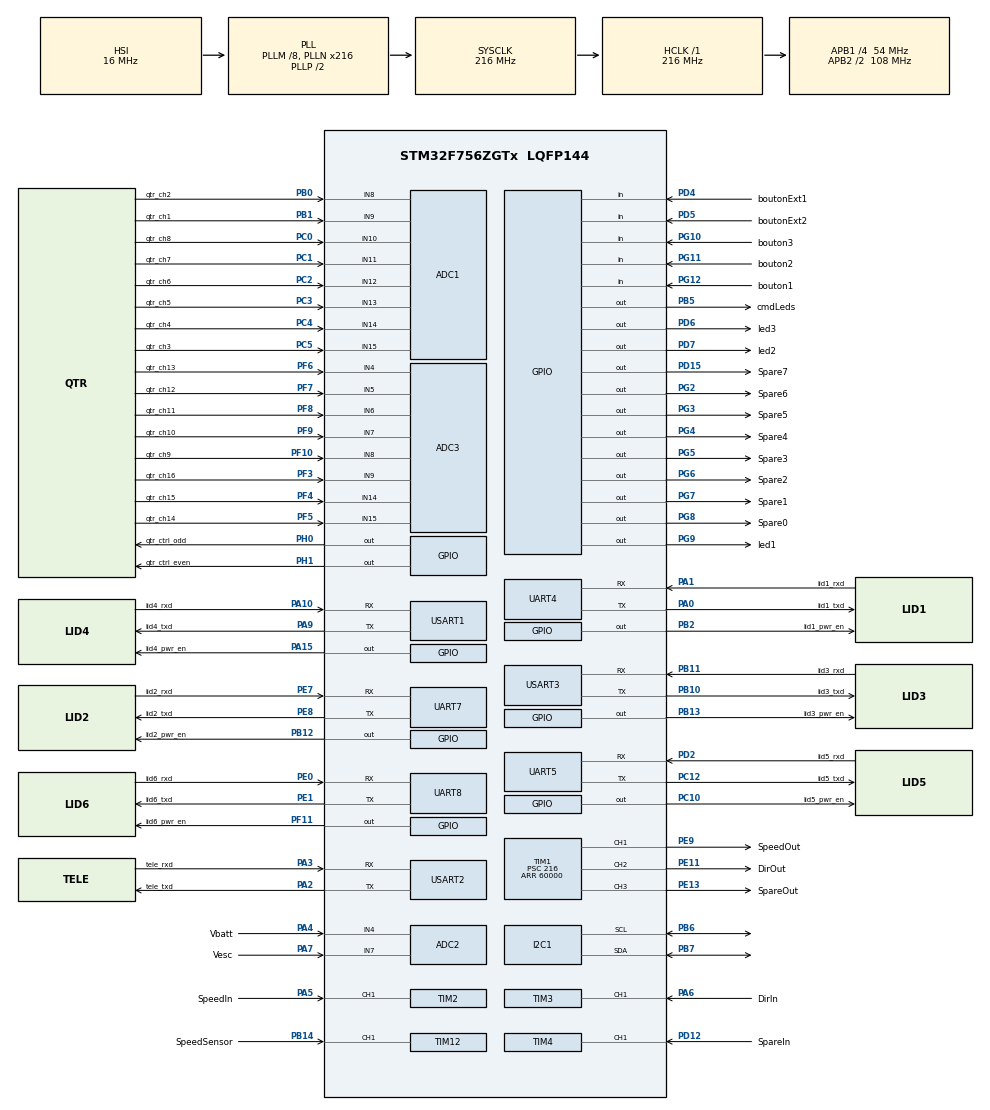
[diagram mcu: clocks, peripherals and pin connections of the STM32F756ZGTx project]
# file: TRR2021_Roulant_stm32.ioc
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ADC1.Channel-2\#ChannelRegularConversion=ADC_CHANNEL_15
ADC1.NbrOfConversionFlag=1
ADC1.Rank-2\#ChannelRegularConversion=1
ADC1.SamplingTime-2\#ChannelRegularConversion=ADC_SAMPLETIME_3CYCLES
ADC1.master=1
ADC2.Channel-0\#ChannelRegularConversion=ADC_CHANNEL_7
ADC2.NbrOfConversionFlag=1
ADC2.Rank-0\#ChannelRegularConversion=1
ADC2.SamplingTime-0\#ChannelRegularConversion=ADC_SAMPLETIME_3CYCLES
ADC3.Channel-0\#ChannelRegularConversion=ADC_CHANNEL_15
ADC3.NbrOfConversionFlag=1
ADC3.Rank-0\#ChannelRegularConversion=1
ADC3.SamplingTime-0\#ChannelRegularConversion=ADC_SAMPLETIME_3CYCLES
Dma.Request0=UART4_RX
Dma.Request1=UART8_RX
Dma.Request2=UART5_RX
Dma.Request3=UART7_RX
Dma.UART4_RX.0.Direction=DMA_PERIPH_TO_MEMORY
Dma.UART4_RX.0.FIFOMode=DMA_FIFOMODE_DISABLE
Dma.UART4_RX.0.Instance=DMA1_Stream2
Dma.UART4_RX.0.MemDataAlignment=DMA_MDATAALIGN_BYTE
Dma.UART4_RX.0.MemInc=DMA_MINC_ENABLE
Dma.UART4_RX.0.Mode=DMA_NORMAL
Dma.UART4_RX.0.PeriphDataAlignment=DMA_PDATAALIGN_BYTE
Dma.UART4_RX.0.PeriphInc=DMA_PINC_DISABLE
Dma.UART4_RX.0.Priority=DMA_PRIORITY_LOW
Dma.UART5_RX.2.Direction=DMA_PERIPH_TO_MEMORY
Dma.UART5_RX.2.FIFOMode=DMA_FIFOMODE_DISABLE
Dma.UART5_RX.2.Instance=DMA1_Stream0
Dma.UART5_RX.2.MemDataAlignment=DMA_MDATAALIGN_BYTE
Dma.UART5_RX.2.MemInc=DMA_MINC_ENABLE
Dma.UART5_RX.2.Mode=DMA_NORMAL
Dma.UART5_RX.2.PeriphDataAlignment=DMA_PDATAALIGN_BYTE
Dma.UART5_RX.2.PeriphInc=DMA_PINC_DISABLE
Dma.UART5_RX.2.Priority=DMA_PRIORITY_LOW
Dma.UART7_RX.3.Direction=DMA_PERIPH_TO_MEMORY
Dma.UART7_RX.3.FIFOMode=DMA_FIFOMODE_DISABLE
Dma.UART7_RX.3.Instance=DMA1_Stream3
Dma.UART7_RX.3.MemDataAlignment=DMA_MDATAALIGN_BYTE
Dma.UART7_RX.3.MemInc=DMA_MINC_ENABLE
Dma.UART7_RX.3.Mode=DMA_NORMAL
Dma.UART7_RX.3.PeriphDataAlignment=DMA_PDATAALIGN_BYTE
Dma.UART7_RX.3.PeriphInc=DMA_PINC_DISABLE
Dma.UART7_RX.3.Priority=DMA_PRIORITY_LOW
Dma.UART8_RX.1.Direction=DMA_PERIPH_TO_MEMORY
Dma.UART8_RX.1.FIFOMode=DMA_FIFOMODE_DISABLE
Dma.UART8_RX.1.Instance=DMA1_Stream6
Dma.UART8_RX.1.MemDataAlignment=DMA_MDATAALIGN_BYTE
Dma.UART8_RX.1.MemInc=DMA_MINC_ENABLE
Dma.UART8_RX.1.Mode=DMA_NORMAL
Dma.UART8_RX.1.PeriphDataAlignment=DMA_PDATAALIGN_BYTE
Dma.UART8_RX.1.PeriphInc=DMA_PINC_DISABLE
Dma.UART8_RX.1.Priority=DMA_PRIORITY_LOW
I2C1.Timing=0x20404768
Mcu.Family=STM32F7
Mcu.Name=STM32F756ZGTx
Mcu.Package=LQFP144
NVIC.DMA1_Stream0_IRQn=true\:0\:0\:false\:false\:true\:false\:true
NVIC.DMA1_Stream2_IRQn=true\:0\:0\:false\:false\:true\:false\:true
NVIC.DMA1_Stream3_IRQn=true\:0\:0\:false\:false\:true\:false\:true
NVIC.DMA1_Stream6_IRQn=true\:0\:0\:false\:false\:true\:false\:true
NVIC.PriorityGroup=NVIC_PRIORITYGROUP_4
NVIC.TIM2_IRQn=true\:0\:0\:false\:false\:true\:true\:true
NVIC.TIM3_IRQn=true\:0\:0\:false\:false\:true\:true\:true
NVIC.TIM4_IRQn=true\:0\:0\:false\:false\:true\:true\:true
NVIC.TIM8_BRK_TIM12_IRQn=true\:0\:0\:false\:false\:true\:true\:true
NVIC.UART4_IRQn=true\:0\:0\:false\:false\:true\:true\:true
NVIC.UART5_IRQn=true\:0\:0\:false\:false\:true\:true\:true
NVIC.UART7_IRQn=true\:0\:0\:false\:false\:true\:true\:true
NVIC.UART8_IRQn=true\:0\:0\:false\:false\:true\:true\:true
PA0/WKUP.GPIO_Label=lid1_txd
PA0/WKUP.GPIO_PuPd=GPIO_PULLUP
PA0/WKUP.Mode=Asynchronous
PA0/WKUP.Signal=UART4_TX
PA1.GPIO_Label=lid1_rxd
PA1.GPIO_PuPd=GPIO_PULLUP
PA1.Mode=Asynchronous
PA1.Signal=UART4_RX
PA10.GPIO_Label=lid4_rxd
PA10.Mode=Asynchronous
PA10.Signal=USART1_RX
PA13.Signal=SYS_JTMS-SWDIO
PA14.Signal=SYS_JTCK-SWCLK
PA15.GPIO_Label=lid4_pwr_en
PA15.Signal=GPIO_Output
PA2.GPIO_Label=tele_txd
PA2.GPIO_Speed=GPIO_SPEED_FREQ_LOW
PA2.Mode=Asynchronous
PA2.Signal=USART2_TX
PA3.GPIO_Label=tele_rxd
PA3.GPIO_Speed=GPIO_SPEED_FREQ_LOW
PA3.Mode=Asynchronous
PA3.Signal=USART2_RX
PA4.GPIO_Label=Vbatt
PA4.Signal=ADCx_IN4
PA5.GPIO_Label=SpeedIn
PA5.Signal=S_TIM2_CH1_ETR
PA6.GPIO_Label=DirIn
PA6.Signal=S_TIM3_CH1
PA7.GPIO_Label=Vesc
PA7.Signal=ADCx_IN7
PA9.GPIO_Label=lid4_txd
PA9.Mode=Asynchronous
PA9.Signal=USART1_TX
PB0.GPIO_Label=qtr_ch2
PB0.Signal=ADCx_IN8
PB1.GPIO_Label=qtr_ch1
PB1.Signal=ADCx_IN9
PB10.GPIO_Label=lid3_txd
PB10.Mode=Asynchronous
PB10.Signal=USART3_TX
PB11.GPIO_Label=lid3_rxd
PB11.Mode=Asynchronous
PB11.Signal=USART3_RX
PB12.GPIO_Label=lid2_pwr_en
PB12.Signal=GPIO_Output
PB13.GPIO_Label=lid3_pwr_en
PB13.Signal=GPIO_Output
PB14.GPIO_Label=SpeedSensor
PB14.Signal=S_TIM12_CH1
PB2.GPIO_Label=lid1_pwr_en
PB2.Signal=GPIO_Output
PB5.GPIO_Label=cmdLeds
PB5.Signal=GPIO_Output
PB6.Mode=I2C
PB6.Signal=I2C1_SCL
PB7.Mode=I2C
PB7.Signal=I2C1_SDA
PC0.GPIO_Label=qtr_ch8
PC0.Signal=ADCx_IN10
PC1.GPIO_Label=qtr_ch7
PC1.Signal=ADCx_IN11
PC10.GPIO_Label=lid5_pwr_en
PC10.Signal=GPIO_Output
PC12.GPIO_Label=lid5_txd
PC12.GPIO_PuPd=GPIO_PULLUP
PC12.Mode=Asynchronous
PC12.Signal=UART5_TX
PC2.GPIO_Label=qtr_ch6
PC2.Signal=ADCx_IN12
PC3.GPIO_Label=qtr_ch5
PC3.Signal=ADCx_IN13
PC4.GPIO_Label=qtr_ch4
PC4.Signal=ADCx_IN14
PC5.GPIO_Label=qtr_ch3
PC5.Signal=ADCx_IN15
PD12.GPIO_Label=SpareIn
PD12.GPIO_PuPd=GPIO_PULLUP
PD12.Signal=S_TIM4_CH1
PD15.GPIO_Label=Spare7
PD15.Signal=GPIO_Output
PD2.GPIO_Label=lid5_rxd
PD2.GPIO_PuPd=GPIO_PULLUP
PD2.Mode=Asynchronous
PD2.Signal=UART5_RX
PD4.GPIO_Label=boutonExt1
PD4.Signal=GPIO_Input
PD5.GPIO_Label=boutonExt2
PD5.Signal=GPIO_Input
PD6.GPIO_Label=led3
PD6.Signal=GPIO_Output
PD7.GPIO_Label=led2
PD7.Signal=GPIO_Output
PE0.GPIO_Label=lid6_rxd
PE0.GPIO_PuPd=GPIO_PULLUP
PE0.Mode=Asynchronous
PE0.Signal=UART8_RX
PE1.GPIO_Label=lid6_txd
PE1.GPIO_PuPd=GPIO_PULLUP
PE1.Mode=Asynchronous
PE1.Signal=UART8_TX
PE11.GPIO_Label=DirOut
PE11.Signal=S_TIM1_CH2
PE13.GPIO_Label=SpareOut
PE13.Signal=S_TIM1_CH3
PE7.GPIO_Label=lid2_rxd
PE7.GPIO_PuPd=GPIO_PULLUP
PE7.Mode=Asynchronous
PE7.Signal=UART7_RX
PE8.GPIO_Label=lid2_txd
PE8.GPIO_PuPd=GPIO_PULLUP
PE8.Mode=Asynchronous
PE8.Signal=UART7_TX
PE9.GPIO_Label=SpeedOut
PE9.Signal=S_TIM1_CH1
PF10.GPIO_Label=qtr_ch9
PF10.Mode=IN8
PF10.Signal=ADC3_IN8
PF11.GPIO_Label=lid6_pwr_en
PF11.Signal=GPIO_Output
PF3.GPIO_Label=qtr_ch16
PF3.Mode=IN9
PF3.Signal=ADC3_IN9
PF4.GPIO_Label=qtr_ch15
PF4.Mode=IN14
PF4.Signal=ADC3_IN14
PF5.GPIO_Label=qtr_ch14
PF5.Mode=IN15
PF5.Signal=ADC3_IN15
PF6.GPIO_Label=qtr_ch13
PF6.Mode=IN4
PF6.Signal=ADC3_IN4
PF7.GPIO_Label=qtr_ch12
PF7.Mode=IN5
PF7.Signal=ADC3_IN5
PF8.GPIO_Label=qtr_ch11
PF8.Mode=IN6
PF8.Signal=ADC3_IN6
PF9.GPIO_Label=qtr_ch10
PF9.Mode=IN7
PF9.Signal=ADC3_IN7
PG10.GPIO_Label=bouton3
PG10.Signal=GPIO_Input
PG11.GPIO_Label=bouton2
PG11.Signal=GPIO_Input
PG12.GPIO_Label=bouton1
PG12.Signal=GPIO_Input
PG2.GPIO_Label=Spare6
PG2.Signal=GPIO_Output
PG3.GPIO_Label=Spare5
PG3.Signal=GPIO_Output
PG4.GPIO_Label=Spare4
PG4.Signal=GPIO_Output
PG5.GPIO_Label=Spare3
PG5.Signal=GPIO_Output
PG6.GPIO_Label=Spare2
PG6.Signal=GPIO_Output
PG7.GPIO_Label=Spare1
PG7.Signal=GPIO_Output
PG8.GPIO_Label=Spare0
PG8.Signal=GPIO_Output
PG9.GPIO_Label=led1
PG9.Signal=GPIO_Output
PH0/OSC_IN.GPIO_Label=qtr_ctrl_odd
PH0/OSC_IN.Signal=GPIO_Output
PH1/OSC_OUT.GPIO_Label=qtr_ctrl_even
PH1/OSC_OUT.Signal=GPIO_Output
ProjectManager.HeapSize=0x200
ProjectManager.StackSize=0x400
ProjectManager.TargetToolchain=STM32CubeIDE
RCC.AHBFreq_Value=216000000
RCC.APB1CLKDivider=RCC_HCLK_DIV4
RCC.APB1Freq_Value=54000000
RCC.APB1TimFreq_Value=108000000
RCC.APB2CLKDivider=RCC_HCLK_DIV2
RCC.APB2Freq_Value=108000000
RCC.APB2TimFreq_Value=216000000
RCC.CortexFreq_Value=216000000
RCC.HCLKFreq_Value=216000000
RCC.HSE_VALUE=25000000
RCC.HSI_VALUE=16000000
RCC.LSE_VALUE=32768
RCC.PLLM=8
RCC.PLLN=216
RCC.SYSCLKFreq_VALUE=216000000
RCC.SYSCLKSource=RCC_SYSCLKSOURCE_PLLCLK
RCC.USBFreq_Value=216000000
RCC.VCOOutputFreq_Value=432000000
SH.ADCx_IN10.0=ADC1_IN10,IN10
SH.ADCx_IN11.0=ADC1_IN11,IN11
SH.ADCx_IN12.0=ADC1_IN12,IN12
SH.ADCx_IN13.0=ADC1_IN13,IN13
SH.ADCx_IN14.0=ADC1_IN14,IN14
SH.ADCx_IN15.0=ADC1_IN15,IN15
SH.ADCx_IN4.0=ADC2_IN4,IN4
SH.ADCx_IN7.0=ADC2_IN7,IN7
SH.ADCx_IN8.0=ADC1_IN8,IN8
SH.ADCx_IN9.0=ADC1_IN9,IN9
SH.S_TIM12_CH1.0=TIM12_CH1,PWM_Input_1
SH.S_TIM1_CH1.0=TIM1_CH1,PWM Generation1 CH1
SH.S_TIM1_CH2.0=TIM1_CH2,PWM Generation2 CH2
SH.S_TIM1_CH3.0=TIM1_CH3,PWM Generation3 CH3
SH.S_TIM2_CH1_ETR.0=TIM2_CH1,PWM_Input_1
SH.S_TIM3_CH1.0=TIM3_CH1,PWM_Input_1
SH.S_TIM4_CH1.0=TIM4_CH1,PWM_Input_1
TIM1.Channel-PWM\ Generation1\ CH1=TIM_CHANNEL_1
TIM1.Channel-PWM\ Generation2\ CH2=TIM_CHANNEL_2
TIM1.Channel-PWM\ Generation3\ CH3=TIM_CHANNEL_3
TIM1.Period=60000
TIM1.Prescaler=216
TIM1.Pulse-PWM\ Generation1\ CH1=1500
TIM1.Pulse-PWM\ Generation2\ CH2=1000
TIM12.Period=65535
TIM12.Prescaler=108
TIM2.Period=65535
TIM2.Prescaler=108
TIM3.Period=65535
TIM3.Prescaler=108
TIM4.Period=65535
TIM4.Prescaler=108
UART5.DMADisableonRxErrorParam=UART_ADVFEATURE_DMA_ENABLEONRXERROR
UART5.OverrunDisableParam=UART_ADVFEATURE_OVERRUN_DISABLE
USART1.VirtualMode-Asynchronous=VM_ASYNC
USART2.VirtualMode-Asynchronous=VM_ASYNC
USART3.VirtualMode-Asynchronous=VM_ASYNC
VP_TIM12_VS_ClockSourceINT.Mode=Internal
VP_TIM1_VS_ClockSourceINT.Mode=Internal
VP_TIM2_VS_ClockSourceINT.Mode=Internal
VP_TIM3_VS_ClockSourceINT.Mode=Internal
VP_TIM4_VS_ClockSourceINT.Mode=Internal
VP_TIM8_VS_ClockSourceINT.Mode=Internal
board=custom

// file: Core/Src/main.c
/* USER CODE BEGIN Header */
/**
  ******************************************************************************
  * @file           : main.c
  * @brief          : Main program body
  ******************************************************************************
  * @attention
  *
  * <h2><center>&copy; Copyright (c) 2021 STMicroelectronics.
  * All rights reserved.</center></h2>
  *
  * This software component is licensed by ST under BSD 3-Clause license,
  * the "License"; You may not use this file except in compliance with the
  * License. You may obtain a copy of the License at:
  *                        opensource.org/licenses/BSD-3-Clause
  *
  ******************************************************************************
  */
/* USER CODE END Header */
#include "main.h"

/* USER CODE BEGIN Includes */
#include "stdio.h"
#include "tfminiplus.h"
#include "radio_commandes.h"
#include "imu.h"
#include "pid.h"
#include "algo_suivi_bords.h"
#include "parametres_configuration.h"
#include "telemetrie.h"
/* USER CODE END Includes */

/* USER CODE BEGIN PTD */
typedef enum { automate_principal_radio, automate_principal_autonome, automate_principal_shell } eEtatsAutomatePrincipal;
/* USER CODE END PTD */

ADC_HandleTypeDef hadc1;
ADC_HandleTypeDef hadc2;
ADC_HandleTypeDef hadc3;

I2C_HandleTypeDef hi2c1;

TIM_HandleTypeDef htim1;
TIM_HandleTypeDef htim2;
TIM_HandleTypeDef htim3;
TIM_HandleTypeDef htim4;
TIM_HandleTypeDef htim8;
TIM_HandleTypeDef htim12;

UART_HandleTypeDef huart4;
UART_HandleTypeDef huart5;
UART_HandleTypeDef huart7;
UART_HandleTypeDef huart8;
UART_HandleTypeDef huart1;
UART_HandleTypeDef huart2;
UART_HandleTypeDef huart3;
DMA_HandleTypeDef hdma_uart4_rx;
DMA_HandleTypeDef hdma_uart5_rx;
DMA_HandleTypeDef hdma_uart7_rx;
DMA_HandleTypeDef hdma_uart8_rx;

/* USER CODE BEGIN PV */
extern int gUpdateGyro;
extern eEtatsAutomateAutomatique etat_automate_automatique;
//extern st_telemetrie gTelemetrie;

eEtatsAutomatePrincipal etat_automate_principal;
/* USER CODE END PV */

void SystemClock_Config(void);
static void MX_GPIO_Init(void);
static void MX_I2C1_Init(void);
static void MX_TIM1_Init(void);
static void MX_TIM2_Init(void);
static void MX_TIM3_Init(void);
static void MX_TIM4_Init(void);
static void MX_TIM8_Init(void);
static void MX_UART4_Init(void);
static void MX_UART5_Init(void);
static void MX_UART7_Init(void);
static void MX_UART8_Init(void);
static void MX_USART1_UART_Init(void);
static void MX_USART2_UART_Init(void);
static void MX_USART3_UART_Init(void);
static void MX_ADC1_Init(void);
static void MX_ADC3_Init(void);
static void MX_ADC2_Init(void);
static void MX_DMA_Init(void);
static void MX_TIM12_Init(void);
/* USER CODE BEGIN PFP */
extern void shell();
/* USER CODE END PFP */

/* USER CODE BEGIN 0 */
int __io_putchar(int ch)
{

	uint8_t ch8=ch;

	HAL_UART_Transmit(&huart2,(uint8_t *)&ch8,1,HAL_MAX_DELAY);

	return ch;

}

int __io_getchar()
{

	int ch8;
	HAL_StatusTypeDef retour;

	ch8 = ' ';

	do {
		retour = HAL_UART_Receive(&huart2,(uint8_t*)&ch8,1,HAL_MAX_DELAY);
		//delay_ms(1);
	} while(retour != HAL_OK);

		if(retour != HAL_OK)
			ch8 = -1;

return ch8;

}

/* USER CODE END 0 */

int main(void)
{
  /* USER CODE BEGIN 1 */
	uint32_t current_time;
	uint8_t filtre_declenchement_auto;
	uint32_t last_time_gyro;
	uint16_t temps_appui_boutonext1, temps_relachement_boutonext1;
	uint16_t temps_appui_boutonext2;
	float direction, throttle, distance, distance_precedente, vitesse;
	st_tele_element *pTeleElement;
	st_context_robot robot_contexte;
	int erreur;
  /* USER CODE END 1 */

  /* MCU Configuration--------------------------------------------------------*/

  /* Reset of all peripherals, Initializes the Flash interface and the Systick. */
  HAL_Init();

  /* Configure the system clock */
  SystemClock_Config();

  /* Initialize all configured peripherals */
  MX_GPIO_Init();
  MX_DMA_Init();
  MX_I2C1_Init();
  MX_TIM1_Init();
  MX_TIM2_Init();
  MX_TIM3_Init();
  MX_TIM4_Init();
  MX_TIM8_Init();
  MX_UART4_Init();
  MX_UART5_Init();
  MX_UART7_Init();
  MX_UART8_Init();
  MX_USART1_UART_Init();
  MX_USART2_UART_Init();
  MX_USART3_UART_Init();
  MX_ADC1_Init();
  MX_ADC3_Init();
  MX_ADC2_Init();

  MX_TIM12_Init();
  /* USER CODE BEGIN 2 */

  printf("+++++++ Buggy TRR 2022 Roulant +++++++\r\n");

  // Initialisation des Lidars
  tfminiplus_init();

  // Initialisation de la gestion radio et commande vehicule
  init_radio_commandes();

  // Récupération des parametres de conf
  paramConf_restaure();

  // Gyro
  if(gyro_init() == GYRO_OK)
  {
	  last_time_gyro = HAL_GetTick();
	  while(gyro_is_calibrated())
	  {
		  HAL_Delay(1);
		  current_time = HAL_GetTick();
		  gyro_auto_calibrate(current_time - last_time_gyro);
		  last_time_gyro = current_time;
	  }
	  printf("Gyro calibrated\r\n");
	  gUpdateGyro = 1;
	  gyro_reset_heading();
  }
  else
	  printf("Erreur d'initialisation du Gyro\r\n");

  // Télémetrie
  telemetrie_init();
  pTeleElement = telemetrie_pt_enreg_en_cours();
  erreur = 0;

  // Initialisation des variables
  temps_appui_boutonext1 = 0;
  temps_relachement_boutonext1 = 0;
  temps_appui_boutonext2 = 0;
  distance = 0;
  distance_precedente = 0;

  /* USER CODE END 2 */

  /* Infinite loop */
  while (1)
  {

    /* USER CODE BEGIN 3 */
	  if(HAL_GPIO_ReadPin(boutonExt1_GPIO_Port, boutonExt1_Pin)==GPIO_PIN_RESET)
	  {
		  temps_appui_boutonext1 += 10; // La durée d'appui du bouton est allongée de 10 ms
		  temps_relachement_boutonext1 = 0;
	  }
	  else
	  {
		  temps_appui_boutonext1 = 0;
		  if(temps_relachement_boutonext1 < 60000) // on limite sinon le compteur partirait en dépassement
			  temps_relachement_boutonext1 += 10;
	  }
	  if(HAL_GPIO_ReadPin(boutonExt2_GPIO_Port, boutonExt2_Pin)==GPIO_PIN_RESET)
		  temps_appui_boutonext2 += 10; // La durée d'appui du bouton est allongée de 10 ms
	  else
		  temps_appui_boutonext2 = 0;

	  gyro_update(0.01);

	  switch(etat_automate_principal)
	  {
	  case automate_principal_radio :
		  // Bandeau de lumière couleur xxx
		  // Par défaut aujourd'hui allume led verte
		  HAL_GPIO_WritePin(led1_GPIO_Port, led1_Pin, GPIO_PIN_SET);
		  HAL_GPIO_WritePin(led2_GPIO_Port, led2_Pin, GPIO_PIN_RESET);
		  HAL_GPIO_WritePin(led3_GPIO_Port, led3_Pin, GPIO_PIN_SET);

		  if(temps_appui_boutonext1 > 1000)
		  {
			  algo_init(&robot_contexte);
			  filtre_declenchement_auto = 0;
			  etat_automate_principal = automate_principal_autonome;
		  }
		  else if(temps_appui_boutonext2 > 1000)
		  {
			  etat_automate_principal = automate_principal_shell;
		  }
		  else
		  {
			  // On reste dans l'état actuel.
			  // On recopie les commandes de la radio vers le véhicule
				radio_dir_get(&direction);
				radio_throttle_get(&throttle);
				vehicule_dir_set(direction);
				vehicule_throttle_set(throttle);

//				vehicule_distance_aimant_get(&distance);
//				vitesse = (distance-distance_precedente)/0.01;
//				distance_precedente = distance;
//
//				printf("%f;%f;%f\r\n", throttle, vitesse, distance);
		  }
		  break;
	  case automate_principal_autonome :
		  // Bandeau de lumière couleur xxx
		  // Par défaut aujourd'hui allume led rouge
		  HAL_GPIO_WritePin(led1_GPIO_Port, led1_Pin, GPIO_PIN_RESET);
		  HAL_GPIO_WritePin(led2_GPIO_Port, led2_Pin, GPIO_PIN_SET);
		  HAL_GPIO_WritePin(led3_GPIO_Port, led3_Pin, GPIO_PIN_SET);

		  // On attend le relachement du bouton puis 2 secondes,
		  // le temps que la personne retire complètement son doigt de l'environnement du robot
		  if((temps_relachement_boutonext1>2000) && (filtre_declenchement_auto == 0))
			  filtre_declenchement_auto = 1;

		  if(filtre_declenchement_auto == 1)
			  // Appel automate
			  algo_decouverte(&robot_contexte, 0.01);

		  // Si le pilote tente de reprendre le controle passage immédiat des commandes
		  // Si le tour de piste en automatique est fini alors passage des commandes à la radio
		  if((radio_isThereCommand() != 0) || (etat_automate_automatique == automate_auto_fini))
		  {
			  printf("T;Fin;\r\n");
			  etat_automate_principal = automate_principal_radio;

		  }
//		  else
//		  {
//			  // Appel de l'automate automatique
//		  }
		  break;
	  case automate_principal_shell :
		  // Bandeau de lumière couleur xxx
		  // Par défaut aujourd'hui allume led bleue
		  HAL_GPIO_WritePin(led1_GPIO_Port, led1_Pin, GPIO_PIN_SET);
		  HAL_GPIO_WritePin(led2_GPIO_Port, led2_Pin, GPIO_PIN_SET);
		  HAL_GPIO_WritePin(led3_GPIO_Port, led3_Pin, GPIO_PIN_RESET);

		  // Lancement du shell
		  shell();

		  telemetrie_init();
		  pTeleElement = telemetrie_pt_enreg_en_cours();
		  erreur = 0;

		  etat_automate_principal = automate_principal_radio;
		  break;
	  default :
		  etat_automate_principal = automate_principal_radio;
		  break;

	  }

	  // Iteration de l'automate principale toutes les 10 ms.
	  HAL_Delay(10);
  }
  /* USER CODE END 3 */
}

void SystemClock_Config(void)
{
  RCC_OscInitTypeDef RCC_OscInitStruct = {0};
  RCC_ClkInitTypeDef RCC_ClkInitStruct = {0};
  RCC_PeriphCLKInitTypeDef PeriphClkInitStruct = {0};

  /** Configure the main internal regulator output voltage
  */
  __HAL_RCC_PWR_CLK_ENABLE();
  __HAL_PWR_VOLTAGESCALING_CONFIG(PWR_REGULATOR_VOLTAGE_SCALE1);
  /** Initializes the RCC Oscillators according to the specified parameters
  * in the RCC_OscInitTypeDef structure.
  */
  RCC_OscInitStruct.OscillatorType = RCC_OSCILLATORTYPE_HSI;
  RCC_OscInitStruct.HSIState = RCC_HSI_ON;
  RCC_OscInitStruct.HSICalibrationValue = RCC_HSICALIBRATION_DEFAULT;
  RCC_OscInitStruct.PLL.PLLState = RCC_PLL_ON;
  RCC_OscInitStruct.PLL.PLLSource = RCC_PLLSOURCE_HSI;
  RCC_OscInitStruct.PLL.PLLM = 8;
  RCC_OscInitStruct.PLL.PLLN = 216;
  RCC_OscInitStruct.PLL.PLLP = RCC_PLLP_DIV2;
  RCC_OscInitStruct.PLL.PLLQ = 2;
  if (HAL_RCC_OscConfig(&RCC_OscInitStruct) != HAL_OK)
  {
    Error_Handler();
  }
  /** Activate the Over-Drive mode
  */
  if (HAL_PWREx_EnableOverDrive() != HAL_OK)
  {
    Error_Handler();
  }
  /** Initializes the CPU, AHB and APB buses clocks
  */
  RCC_ClkInitStruct.ClockType = RCC_CLOCKTYPE_HCLK|RCC_CLOCKTYPE_SYSCLK
                              |RCC_CLOCKTYPE_PCLK1|RCC_CLOCKTYPE_PCLK2;
  RCC_ClkInitStruct.SYSCLKSource = RCC_SYSCLKSOURCE_PLLCLK;
  RCC_ClkInitStruct.AHBCLKDivider = RCC_SYSCLK_DIV1;
  RCC_ClkInitStruct.APB1CLKDivider = RCC_HCLK_DIV4;
  RCC_ClkInitStruct.APB2CLKDivider = RCC_HCLK_DIV2;

  if (HAL_RCC_ClockConfig(&RCC_ClkInitStruct, FLASH_LATENCY_7) != HAL_OK)
  {
    Error_Handler();
  }
  PeriphClkInitStruct.PeriphClockSelection = RCC_PERIPHCLK_USART1|RCC_PERIPHCLK_USART2
                              |RCC_PERIPHCLK_USART3|RCC_PERIPHCLK_UART4
                              |RCC_PERIPHCLK_UART5|RCC_PERIPHCLK_UART7
                              |RCC_PERIPHCLK_UART8|RCC_PERIPHCLK_I2C1;
  PeriphClkInitStruct.Usart1ClockSelection = RCC_USART1CLKSOURCE_PCLK2;
  PeriphClkInitStruct.Usart2ClockSelection = RCC_USART2CLKSOURCE_PCLK1;
  PeriphClkInitStruct.Usart3ClockSelection = RCC_USART3CLKSOURCE_PCLK1;
  PeriphClkInitStruct.Uart4ClockSelection = RCC_UART4CLKSOURCE_PCLK1;
  PeriphClkInitStruct.Uart5ClockSelection = RCC_UART5CLKSOURCE_PCLK1;
  PeriphClkInitStruct.Uart7ClockSelection = RCC_UART7CLKSOURCE_PCLK1;
  PeriphClkInitStruct.Uart8ClockSelection = RCC_UART8CLKSOURCE_PCLK1;
  PeriphClkInitStruct.I2c1ClockSelection = RCC_I2C1CLKSOURCE_PCLK1;
  if (HAL_RCCEx_PeriphCLKConfig(&PeriphClkInitStruct) != HAL_OK)
  {
    Error_Handler();
  }
}

static void MX_ADC1_Init(void)
{

  ADC_ChannelConfTypeDef sConfig = {0};

  /** Configure the global features of the ADC (Clock, Resolution, Data Alignment and number of conversion)
  */
  hadc1.Instance = ADC1;
  hadc1.Init.ClockPrescaler = ADC_CLOCK_SYNC_PCLK_DIV4;
  hadc1.Init.Resolution = ADC_RESOLUTION_12B;
  hadc1.Init.ScanConvMode = ADC_SCAN_DISABLE;
  hadc1.Init.ContinuousConvMode = DISABLE;
  hadc1.Init.DiscontinuousConvMode = DISABLE;
  hadc1.Init.ExternalTrigConvEdge = ADC_EXTERNALTRIGCONVEDGE_NONE;
  hadc1.Init.ExternalTrigConv = ADC_SOFTWARE_START;
  hadc1.Init.DataAlign = ADC_DATAALIGN_RIGHT;
  hadc1.Init.NbrOfConversion = 1;
  hadc1.Init.DMAContinuousRequests = DISABLE;
  hadc1.Init.EOCSelection = ADC_EOC_SINGLE_CONV;
  if (HAL_ADC_Init(&hadc1) != HAL_OK)
  {
    Error_Handler();
  }
  /** Configure for the selected ADC regular channel its corresponding rank in the sequencer and its sample time.
  */
  sConfig.Channel = ADC_CHANNEL_15;
  sConfig.Rank = ADC_REGULAR_RANK_1;
  sConfig.SamplingTime = ADC_SAMPLETIME_3CYCLES;
  if (HAL_ADC_ConfigChannel(&hadc1, &sConfig) != HAL_OK)
  {
    Error_Handler();
  }

}

static void MX_ADC2_Init(void)
{

  ADC_ChannelConfTypeDef sConfig = {0};

  /** Configure the global features of the ADC (Clock, Resolution, Data Alignment and number of conversion)
  */
  hadc2.Instance = ADC2;
  hadc2.Init.ClockPrescaler = ADC_CLOCK_SYNC_PCLK_DIV4;
  hadc2.Init.Resolution = ADC_RESOLUTION_12B;
  hadc2.Init.ScanConvMode = ADC_SCAN_DISABLE;
  hadc2.Init.ContinuousConvMode = DISABLE;
  hadc2.Init.DiscontinuousConvMode = DISABLE;
  hadc2.Init.ExternalTrigConvEdge = ADC_EXTERNALTRIGCONVEDGE_NONE;
  hadc2.Init.ExternalTrigConv = ADC_SOFTWARE_START;
  hadc2.Init.DataAlign = ADC_DATAALIGN_RIGHT;
  hadc2.Init.NbrOfConversion = 1;
  hadc2.Init.DMAContinuousRequests = DISABLE;
  hadc2.Init.EOCSelection = ADC_EOC_SINGLE_CONV;
  if (HAL_ADC_Init(&hadc2) != HAL_OK)
  {
    Error_Handler();
  }
  /** Configure for the selected ADC regular channel its corresponding rank in the sequencer and its sample time.
  */
  sConfig.Channel = ADC_CHANNEL_7;
  sConfig.Rank = ADC_REGULAR_RANK_1;
  sConfig.SamplingTime = ADC_SAMPLETIME_3CYCLES;
  if (HAL_ADC_ConfigChannel(&hadc2, &sConfig) != HAL_OK)
  {
    Error_Handler();
  }

}

static void MX_ADC3_Init(void)
{

  ADC_ChannelConfTypeDef sConfig = {0};

  /** Configure the global features of the ADC (Clock, Resolution, Data Alignment and number of conversion)
  */
  hadc3.Instance = ADC3;
  hadc3.Init.ClockPrescaler = ADC_CLOCK_SYNC_PCLK_DIV4;
  hadc3.Init.Resolution = ADC_RESOLUTION_12B;
  hadc3.Init.ScanConvMode = ADC_SCAN_DISABLE;
  hadc3.Init.ContinuousConvMode = DISABLE;
  hadc3.Init.DiscontinuousConvMode = DISABLE;
  hadc3.Init.ExternalTrigConvEdge = ADC_EXTERNALTRIGCONVEDGE_NONE;
  hadc3.Init.ExternalTrigConv = ADC_SOFTWARE_START;
  hadc3.Init.DataAlign = ADC_DATAALIGN_RIGHT;
  hadc3.Init.NbrOfConversion = 1;
  hadc3.Init.DMAContinuousRequests = DISABLE;
  hadc3.Init.EOCSelection = ADC_EOC_SINGLE_CONV;
  if (HAL_ADC_Init(&hadc3) != HAL_OK)
  {
    Error_Handler();
  }
  /** Configure for the selected ADC regular channel its corresponding rank in the sequencer and its sample time.
  */
  sConfig.Channel = ADC_CHANNEL_15;
  sConfig.Rank = ADC_REGULAR_RANK_1;
  sConfig.SamplingTime = ADC_SAMPLETIME_3CYCLES;
  if (HAL_ADC_ConfigChannel(&hadc3, &sConfig) != HAL_OK)
  {
    Error_Handler();
  }

}

static void MX_I2C1_Init(void)
{

  hi2c1.Instance = I2C1;
  hi2c1.Init.Timing = 0x20404768;
  hi2c1.Init.OwnAddress1 = 0;
  hi2c1.Init.AddressingMode = I2C_ADDRESSINGMODE_7BIT;
  hi2c1.Init.DualAddressMode = I2C_DUALADDRESS_DISABLE;
  hi2c1.Init.OwnAddress2 = 0;
  hi2c1.Init.OwnAddress2Masks = I2C_OA2_NOMASK;
  hi2c1.Init.GeneralCallMode = I2C_GENERALCALL_DISABLE;
  hi2c1.Init.NoStretchMode = I2C_NOSTRETCH_DISABLE;
  if (HAL_I2C_Init(&hi2c1) != HAL_OK)
  {
    Error_Handler();
  }
  /** Configure Analogue filter
  */
  if (HAL_I2CEx_ConfigAnalogFilter(&hi2c1, I2C_ANALOGFILTER_ENABLE) != HAL_OK)
  {
    Error_Handler();
  }
  /** Configure Digital filter
  */
  if (HAL_I2CEx_ConfigDigitalFilter(&hi2c1, 0) != HAL_OK)
  {
    Error_Handler();
  }

}

static void MX_TIM1_Init(void)
{

  TIM_ClockConfigTypeDef sClockSourceConfig = {0};
  TIM_MasterConfigTypeDef sMasterConfig = {0};
  TIM_OC_InitTypeDef sConfigOC = {0};
  TIM_BreakDeadTimeConfigTypeDef sBreakDeadTimeConfig = {0};

  htim1.Instance = TIM1;
  htim1.Init.Prescaler = 216;
  htim1.Init.CounterMode = TIM_COUNTERMODE_UP;
  htim1.Init.Period = 60000;
  htim1.Init.ClockDivision = TIM_CLOCKDIVISION_DIV1;
  htim1.Init.RepetitionCounter = 0;
  htim1.Init.AutoReloadPreload = TIM_AUTORELOAD_PRELOAD_DISABLE;
  if (HAL_TIM_Base_Init(&htim1) != HAL_OK)
  {
    Error_Handler();
  }
  sClockSourceConfig.ClockSource = TIM_CLOCKSOURCE_INTERNAL;
  if (HAL_TIM_ConfigClockSource(&htim1, &sClockSourceConfig) != HAL_OK)
  {
    Error_Handler();
  }
  if (HAL_TIM_PWM_Init(&htim1) != HAL_OK)
  {
    Error_Handler();
  }
  sMasterConfig.MasterOutputTrigger = TIM_TRGO_RESET;
  sMasterConfig.MasterOutputTrigger2 = TIM_TRGO2_RESET;
  sMasterConfig.MasterSlaveMode = TIM_MASTERSLAVEMODE_DISABLE;
  if (HAL_TIMEx_MasterConfigSynchronization(&htim1, &sMasterConfig) != HAL_OK)
  {
    Error_Handler();
  }
  sConfigOC.OCMode = TIM_OCMODE_PWM1;
  sConfigOC.Pulse = 1500;
  sConfigOC.OCPolarity = TIM_OCPOLARITY_HIGH;
  sConfigOC.OCNPolarity = TIM_OCNPOLARITY_HIGH;
  sConfigOC.OCFastMode = TIM_OCFAST_DISABLE;
  sConfigOC.OCIdleState = TIM_OCIDLESTATE_RESET;
  sConfigOC.OCNIdleState = TIM_OCNIDLESTATE_RESET;
  if (HAL_TIM_PWM_ConfigChannel(&htim1, &sConfigOC, TIM_CHANNEL_1) != HAL_OK)
  {
    Error_Handler();
  }
  sConfigOC.Pulse = 1000;
  if (HAL_TIM_PWM_ConfigChannel(&htim1, &sConfigOC, TIM_CHANNEL_2) != HAL_OK)
  {
    Error_Handler();
  }
  sConfigOC.Pulse = 0;
  if (HAL_TIM_PWM_ConfigChannel(&htim1, &sConfigOC, TIM_CHANNEL_3) != HAL_OK)
  {
    Error_Handler();
  }
  sBreakDeadTimeConfig.OffStateRunMode = TIM_OSSR_DISABLE;
  sBreakDeadTimeConfig.OffStateIDLEMode = TIM_OSSI_DISABLE;
  sBreakDeadTimeConfig.LockLevel = TIM_LOCKLEVEL_OFF;
  sBreakDeadTimeConfig.DeadTime = 0;
  sBreakDeadTimeConfig.BreakState = TIM_BREAK_DISABLE;
  sBreakDeadTimeConfig.BreakPolarity = TIM_BREAKPOLARITY_HIGH;
  sBreakDeadTimeConfig.BreakFilter = 0;
  sBreakDeadTimeConfig.Break2State = TIM_BREAK2_DISABLE;
  sBreakDeadTimeConfig.Break2Polarity = TIM_BREAK2POLARITY_HIGH;
  sBreakDeadTimeConfig.Break2Filter = 0;
  sBreakDeadTimeConfig.AutomaticOutput = TIM_AUTOMATICOUTPUT_DISABLE;
  if (HAL_TIMEx_ConfigBreakDeadTime(&htim1, &sBreakDeadTimeConfig) != HAL_OK)
  {
    Error_Handler();
  }
  HAL_TIM_MspPostInit(&htim1);

}

static void MX_TIM2_Init(void)
{

  TIM_ClockConfigTypeDef sClockSourceConfig = {0};
  TIM_SlaveConfigTypeDef sSlaveConfig = {0};
  TIM_IC_InitTypeDef sConfigIC = {0};
  TIM_MasterConfigTypeDef sMasterConfig = {0};

  htim2.Instance = TIM2;
  htim2.Init.Prescaler = 108;
  htim2.Init.CounterMode = TIM_COUNTERMODE_UP;
  htim2.Init.Period = 65535;
  htim2.Init.ClockDivision = TIM_CLOCKDIVISION_DIV1;
  htim2.Init.AutoReloadPreload = TIM_AUTORELOAD_PRELOAD_DISABLE;
  if (HAL_TIM_Base_Init(&htim2) != HAL_OK)
  {
    Error_Handler();
  }
  sClockSourceConfig.ClockSource = TIM_CLOCKSOURCE_INTERNAL;
  if (HAL_TIM_ConfigClockSource(&htim2, &sClockSourceConfig) != HAL_OK)
  {
    Error_Handler();
  }
  if (HAL_TIM_IC_Init(&htim2) != HAL_OK)
  {
    Error_Handler();
  }
  sSlaveConfig.SlaveMode = TIM_SLAVEMODE_RESET;
  sSlaveConfig.InputTrigger = TIM_TS_TI1FP1;
  sSlaveConfig.TriggerPolarity = TIM_INPUTCHANNELPOLARITY_RISING;
  sSlaveConfig.TriggerPrescaler = TIM_ICPSC_DIV1;
  sSlaveConfig.TriggerFilter = 0;
  if (HAL_TIM_SlaveConfigSynchro(&htim2, &sSlaveConfig) != HAL_OK)
  {
    Error_Handler();
  }
  sConfigIC.ICPolarity = TIM_INPUTCHANNELPOLARITY_RISING;
  sConfigIC.ICSelection = TIM_ICSELECTION_DIRECTTI;
  sConfigIC.ICPrescaler = TIM_ICPSC_DIV1;
  sConfigIC.ICFilter = 0;
  if (HAL_TIM_IC_ConfigChannel(&htim2, &sConfigIC, TIM_CHANNEL_1) != HAL_OK)
  {
    Error_Handler();
  }
  sConfigIC.ICPolarity = TIM_INPUTCHANNELPOLARITY_FALLING;
  sConfigIC.ICSelection = TIM_ICSELECTION_INDIRECTTI;
  if (HAL_TIM_IC_ConfigChannel(&htim2, &sConfigIC, TIM_CHANNEL_2) != HAL_OK)
  {
    Error_Handler();
  }
  sMasterConfig.MasterOutputTrigger = TIM_TRGO_RESET;
  sMasterConfig.MasterSlaveMode = TIM_MASTERSLAVEMODE_DISABLE;
  if (HAL_TIMEx_MasterConfigSynchronization(&htim2, &sMasterConfig) != HAL_OK)
  {
    Error_Handler();
  }

}

static void MX_TIM3_Init(void)
{

  TIM_ClockConfigTypeDef sClockSourceConfig = {0};
  TIM_SlaveConfigTypeDef sSlaveConfig = {0};
  TIM_IC_InitTypeDef sConfigIC = {0};
  TIM_MasterConfigTypeDef sMasterConfig = {0};

  htim3.Instance = TIM3;
  htim3.Init.Prescaler = 108;
  htim3.Init.CounterMode = TIM_COUNTERMODE_UP;
  htim3.Init.Period = 65535;
  htim3.Init.ClockDivision = TIM_CLOCKDIVISION_DIV1;
  htim3.Init.AutoReloadPreload = TIM_AUTORELOAD_PRELOAD_DISABLE;
  if (HAL_TIM_Base_Init(&htim3) != HAL_OK)
  {
    Error_Handler();
  }
  sClockSourceConfig.ClockSource = TIM_CLOCKSOURCE_INTERNAL;
  if (HAL_TIM_ConfigClockSource(&htim3, &sClockSourceConfig) != HAL_OK)
  {
    Error_Handler();
  }
  if (HAL_TIM_IC_Init(&htim3) != HAL_OK)
  {
    Error_Handler();
  }
  sSlaveConfig.SlaveMode = TIM_SLAVEMODE_RESET;
  sSlaveConfig.InputTrigger = TIM_TS_TI1FP1;
  sSlaveConfig.TriggerPolarity = TIM_INPUTCHANNELPOLARITY_RISING;
  sSlaveConfig.TriggerPrescaler = TIM_ICPSC_DIV1;
  sSlaveConfig.TriggerFilter = 0;
  if (HAL_TIM_SlaveConfigSynchro(&htim3, &sSlaveConfig) != HAL_OK)
  {
    Error_Handler();
  }
  sConfigIC.ICPolarity = TIM_INPUTCHANNELPOLARITY_RISING;
  sConfigIC.ICSelection = TIM_ICSELECTION_DIRECTTI;
  sConfigIC.ICPrescaler = TIM_ICPSC_DIV1;
  sConfigIC.ICFilter = 0;
  if (HAL_TIM_IC_ConfigChannel(&htim3, &sConfigIC, TIM_CHANNEL_1) != HAL_OK)
  {
    Error_Handler();
  }
  sConfigIC.ICPolarity = TIM_INPUTCHANNELPOLARITY_FALLING;
  sConfigIC.ICSelection = TIM_ICSELECTION_INDIRECTTI;
  if (HAL_TIM_IC_ConfigChannel(&htim3, &sConfigIC, TIM_CHANNEL_2) != HAL_OK)
  {
    Error_Handler();
  }
  sMasterConfig.MasterOutputTrigger = TIM_TRGO_RESET;
  sMasterConfig.MasterSlaveMode = TIM_MASTERSLAVEMODE_DISABLE;
  if (HAL_TIMEx_MasterConfigSynchronization(&htim3, &sMasterConfig) != HAL_OK)
  {
    Error_Handler();
  }

}

static void MX_TIM4_Init(void)
{

  TIM_ClockConfigTypeDef sClockSourceConfig = {0};
  TIM_SlaveConfigTypeDef sSlaveConfig = {0};
  TIM_IC_InitTypeDef sConfigIC = {0};
  TIM_MasterConfigTypeDef sMasterConfig = {0};

  htim4.Instance = TIM4;
  htim4.Init.Prescaler = 108;
  htim4.Init.CounterMode = TIM_COUNTERMODE_UP;
  htim4.Init.Period = 65535;
  htim4.Init.ClockDivision = TIM_CLOCKDIVISION_DIV1;
  htim4.Init.AutoReloadPreload = TIM_AUTORELOAD_PRELOAD_DISABLE;
  if (HAL_TIM_Base_Init(&htim4) != HAL_OK)
  {
    Error_Handler();
  }
  sClockSourceConfig.ClockSource = TIM_CLOCKSOURCE_INTERNAL;
  if (HAL_TIM_ConfigClockSource(&htim4, &sClockSourceConfig) != HAL_OK)
  {
    Error_Handler();
  }
  if (HAL_TIM_IC_Init(&htim4) != HAL_OK)
  {
    Error_Handler();
  }
  sSlaveConfig.SlaveMode = TIM_SLAVEMODE_RESET;
  sSlaveConfig.InputTrigger = TIM_TS_TI1FP1;
  sSlaveConfig.TriggerPolarity = TIM_INPUTCHANNELPOLARITY_RISING;
  sSlaveConfig.TriggerPrescaler = TIM_ICPSC_DIV1;
  sSlaveConfig.TriggerFilter = 0;
  if (HAL_TIM_SlaveConfigSynchro(&htim4, &sSlaveConfig) != HAL_OK)
  {
    Error_Handler();
  }
  sConfigIC.ICPolarity = TIM_INPUTCHANNELPOLARITY_RISING;
  sConfigIC.ICSelection = TIM_ICSELECTION_DIRECTTI;
  sConfigIC.ICPrescaler = TIM_ICPSC_DIV1;
  sConfigIC.ICFilter = 0;
  if (HAL_TIM_IC_ConfigChannel(&htim4, &sConfigIC, TIM_CHANNEL_1) != HAL_OK)
  {
    Error_Handler();
  }
  sConfigIC.ICPolarity = TIM_INPUTCHANNELPOLARITY_FALLING;
  sConfigIC.ICSelection = TIM_ICSELECTION_INDIRECTTI;
  if (HAL_TIM_IC_ConfigChannel(&htim4, &sConfigIC, TIM_CHANNEL_2) != HAL_OK)
  {
    Error_Handler();
  }
  sMasterConfig.MasterOutputTrigger = TIM_TRGO_RESET;
  sMasterConfig.MasterSlaveMode = TIM_MASTERSLAVEMODE_DISABLE;
  if (HAL_TIMEx_MasterConfigSynchronization(&htim4, &sMasterConfig) != HAL_OK)
  {
    Error_Handler();
  }

}

static void MX_TIM8_Init(void)
{

  TIM_ClockConfigTypeDef sClockSourceConfig = {0};
  TIM_MasterConfigTypeDef sMasterConfig = {0};

  htim8.Instance = TIM8;
  htim8.Init.Prescaler = 0;
  htim8.Init.CounterMode = TIM_COUNTERMODE_UP;
  htim8.Init.Period = 65535;
  htim8.Init.ClockDivision = TIM_CLOCKDIVISION_DIV1;
  htim8.Init.RepetitionCounter = 0;
  htim8.Init.AutoReloadPreload = TIM_AUTORELOAD_PRELOAD_DISABLE;
  if (HAL_TIM_Base_Init(&htim8) != HAL_OK)
  {
    Error_Handler();
  }
  sClockSourceConfig.ClockSource = TIM_CLOCKSOURCE_INTERNAL;
  if (HAL_TIM_ConfigClockSource(&htim8, &sClockSourceConfig) != HAL_OK)
  {
    Error_Handler();
  }
  sMasterConfig.MasterOutputTrigger = TIM_TRGO_RESET;
  sMasterConfig.MasterOutputTrigger2 = TIM_TRGO2_RESET;
  sMasterConfig.MasterSlaveMode = TIM_MASTERSLAVEMODE_DISABLE;
  if (HAL_TIMEx_MasterConfigSynchronization(&htim8, &sMasterConfig) != HAL_OK)
  {
    Error_Handler();
  }

}

static void MX_TIM12_Init(void)
{

  TIM_ClockConfigTypeDef sClockSourceConfig = {0};
  TIM_SlaveConfigTypeDef sSlaveConfig = {0};
  TIM_IC_InitTypeDef sConfigIC = {0};

  htim12.Instance = TIM12;
  htim12.Init.Prescaler = 108;
  htim12.Init.CounterMode = TIM_COUNTERMODE_UP;
  htim12.Init.Period = 65535;
  htim12.Init.ClockDivision = TIM_CLOCKDIVISION_DIV1;
  htim12.Init.AutoReloadPreload = TIM_AUTORELOAD_PRELOAD_DISABLE;
  if (HAL_TIM_Base_Init(&htim12) != HAL_OK)
  {
    Error_Handler();
  }
  sClockSourceConfig.ClockSource = TIM_CLOCKSOURCE_INTERNAL;
  if (HAL_TIM_ConfigClockSource(&htim12, &sClockSourceConfig) != HAL_OK)
  {
    Error_Handler();
  }
  if (HAL_TIM_IC_Init(&htim12) != HAL_OK)
  {
    Error_Handler();
  }
  sSlaveConfig.SlaveMode = TIM_SLAVEMODE_RESET;
  sSlaveConfig.InputTrigger = TIM_TS_TI1FP1;
  sSlaveConfig.TriggerPolarity = TIM_INPUTCHANNELPOLARITY_RISING;
  sSlaveConfig.TriggerPrescaler = TIM_ICPSC_DIV1;
  sSlaveConfig.TriggerFilter = 0;
  if (HAL_TIM_SlaveConfigSynchro(&htim12, &sSlaveConfig) != HAL_OK)
  {
    Error_Handler();
  }
  sConfigIC.ICPolarity = TIM_INPUTCHANNELPOLARITY_RISING;
  sConfigIC.ICSelection = TIM_ICSELECTION_DIRECTTI;
  sConfigIC.ICPrescaler = TIM_ICPSC_DIV1;
  sConfigIC.ICFilter = 0;
  if (HAL_TIM_IC_ConfigChannel(&htim12, &sConfigIC, TIM_CHANNEL_1) != HAL_OK)
  {
    Error_Handler();
  }
  sConfigIC.ICPolarity = TIM_INPUTCHANNELPOLARITY_FALLING;
  sConfigIC.ICSelection = TIM_ICSELECTION_INDIRECTTI;
  if (HAL_TIM_IC_ConfigChannel(&htim12, &sConfigIC, TIM_CHANNEL_2) != HAL_OK)
  {
    Error_Handler();
  }

}

static void MX_UART4_Init(void)
{

  huart4.Instance = UART4;
  huart4.Init.BaudRate = 115200;
  huart4.Init.WordLength = UART_WORDLENGTH_8B;
  huart4.Init.StopBits = UART_STOPBITS_1;
  huart4.Init.Parity = UART_PARITY_NONE;
  huart4.Init.Mode = UART_MODE_TX_RX;
  huart4.Init.HwFlowCtl = UART_HWCONTROL_NONE;
  huart4.Init.OverSampling = UART_OVERSAMPLING_16;
  huart4.Init.OneBitSampling = UART_ONE_BIT_SAMPLE_DISABLE;
  huart4.AdvancedInit.AdvFeatureInit = UART_ADVFEATURE_NO_INIT;
  if (HAL_UART_Init(&huart4) != HAL_OK)
  {
    Error_Handler();
  }

}

static void MX_UART5_Init(void)
{

  huart5.Instance = UART5;
  huart5.Init.BaudRate = 115200;
  huart5.Init.WordLength = UART_WORDLENGTH_8B;
  huart5.Init.StopBits = UART_STOPBITS_1;
  huart5.Init.Parity = UART_PARITY_NONE;
  huart5.Init.Mode = UART_MODE_TX_RX;
  huart5.Init.HwFlowCtl = UART_HWCONTROL_NONE;
  huart5.Init.OverSampling = UART_OVERSAMPLING_16;
  huart5.Init.OneBitSampling = UART_ONE_BIT_SAMPLE_DISABLE;
  huart5.AdvancedInit.AdvFeatureInit = UART_ADVFEATURE_RXOVERRUNDISABLE_INIT;
  huart5.AdvancedInit.OverrunDisable = UART_ADVFEATURE_OVERRUN_DISABLE;
  if (HAL_UART_Init(&huart5) != HAL_OK)
  {
    Error_Handler();
  }

}

static void MX_UART7_Init(void)
{

  huart7.Instance = UART7;
  huart7.Init.BaudRate = 115200;
  huart7.Init.WordLength = UART_WORDLENGTH_8B;
  huart7.Init.StopBits = UART_STOPBITS_1;
  huart7.Init.Parity = UART_PARITY_NONE;
  huart7.Init.Mode = UART_MODE_TX_RX;
  huart7.Init.HwFlowCtl = UART_HWCONTROL_NONE;
  huart7.Init.OverSampling = UART_OVERSAMPLING_16;
  huart7.Init.OneBitSampling = UART_ONE_BIT_SAMPLE_DISABLE;
  huart7.AdvancedInit.AdvFeatureInit = UART_ADVFEATURE_NO_INIT;
  if (HAL_UART_Init(&huart7) != HAL_OK)
  {
    Error_Handler();
  }

}

static void MX_UART8_Init(void)
{

  huart8.Instance = UART8;
  huart8.Init.BaudRate = 115200;
  huart8.Init.WordLength = UART_WORDLENGTH_8B;
  huart8.Init.StopBits = UART_STOPBITS_1;
  huart8.Init.Parity = UART_PARITY_NONE;
  huart8.Init.Mode = UART_MODE_TX_RX;
  huart8.Init.HwFlowCtl = UART_HWCONTROL_NONE;
  huart8.Init.OverSampling = UART_OVERSAMPLING_16;
  huart8.Init.OneBitSampling = UART_ONE_BIT_SAMPLE_DISABLE;
  huart8.AdvancedInit.AdvFeatureInit = UART_ADVFEATURE_NO_INIT;
  if (HAL_UART_Init(&huart8) != HAL_OK)
  {
    Error_Handler();
  }

}

static void MX_USART1_UART_Init(void)
{

  huart1.Instance = USART1;
  huart1.Init.BaudRate = 115200;
  huart1.Init.WordLength = UART_WORDLENGTH_8B;
  huart1.Init.StopBits = UART_STOPBITS_1;
  huart1.Init.Parity = UART_PARITY_NONE;
  huart1.Init.Mode = UART_MODE_TX_RX;
  huart1.Init.HwFlowCtl = UART_HWCONTROL_NONE;
  huart1.Init.OverSampling = UART_OVERSAMPLING_16;
  huart1.Init.OneBitSampling = UART_ONE_BIT_SAMPLE_DISABLE;
  huart1.AdvancedInit.AdvFeatureInit = UART_ADVFEATURE_NO_INIT;
  if (HAL_UART_Init(&huart1) != HAL_OK)
  {
    Error_Handler();
  }

}

static void MX_USART2_UART_Init(void)
{

  huart2.Instance = USART2;
  huart2.Init.BaudRate = 115200;
  huart2.Init.WordLength = UART_WORDLENGTH_8B;
  huart2.Init.StopBits = UART_STOPBITS_1;
  huart2.Init.Parity = UART_PARITY_NONE;
  huart2.Init.Mode = UART_MODE_TX_RX;
  huart2.Init.HwFlowCtl = UART_HWCONTROL_NONE;
  huart2.Init.OverSampling = UART_OVERSAMPLING_16;
  huart2.Init.OneBitSampling = UART_ONE_BIT_SAMPLE_DISABLE;
  huart2.AdvancedInit.AdvFeatureInit = UART_ADVFEATURE_NO_INIT;
  if (HAL_UART_Init(&huart2) != HAL_OK)
  {
    Error_Handler();
  }

}

static void MX_USART3_UART_Init(void)
{

  huart3.Instance = USART3;
  huart3.Init.BaudRate = 115200;
  huart3.Init.WordLength = UART_WORDLENGTH_8B;
  huart3.Init.StopBits = UART_STOPBITS_1;
  huart3.Init.Parity = UART_PARITY_NONE;
  huart3.Init.Mode = UART_MODE_TX_RX;
  huart3.Init.HwFlowCtl = UART_HWCONTROL_NONE;
  huart3.Init.OverSampling = UART_OVERSAMPLING_16;
  huart3.Init.OneBitSampling = UART_ONE_BIT_SAMPLE_DISABLE;
  huart3.AdvancedInit.AdvFeatureInit = UART_ADVFEATURE_NO_INIT;
  if (HAL_UART_Init(&huart3) != HAL_OK)
  {
    Error_Handler();
  }

}

static void MX_DMA_Init(void)
{

  /* DMA controller clock enable */
  __HAL_RCC_DMA1_CLK_ENABLE();

  /* DMA interrupt init */
  /* DMA1_Stream0_IRQn interrupt configuration */
  HAL_NVIC_SetPriority(DMA1_Stream0_IRQn, 0, 0);
  HAL_NVIC_EnableIRQ(DMA1_Stream0_IRQn);
  /* DMA1_Stream2_IRQn interrupt configuration */
  HAL_NVIC_SetPriority(DMA1_Stream2_IRQn, 0, 0);
  HAL_NVIC_EnableIRQ(DMA1_Stream2_IRQn);
  /* DMA1_Stream3_IRQn interrupt configuration */
  HAL_NVIC_SetPriority(DMA1_Stream3_IRQn, 0, 0);
  HAL_NVIC_EnableIRQ(DMA1_Stream3_IRQn);
  /* DMA1_Stream6_IRQn interrupt configuration */
  HAL_NVIC_SetPriority(DMA1_Stream6_IRQn, 0, 0);
  HAL_NVIC_EnableIRQ(DMA1_Stream6_IRQn);

}

static void MX_GPIO_Init(void)
{
  GPIO_InitTypeDef GPIO_InitStruct = {0};

  /* GPIO Ports Clock Enable */
  __HAL_RCC_GPIOF_CLK_ENABLE();
  __HAL_RCC_GPIOH_CLK_ENABLE();
  __HAL_RCC_GPIOC_CLK_ENABLE();
  __HAL_RCC_GPIOA_CLK_ENABLE();
  __HAL_RCC_GPIOB_CLK_ENABLE();
  __HAL_RCC_GPIOE_CLK_ENABLE();
  __HAL_RCC_GPIOD_CLK_ENABLE();
  __HAL_RCC_GPIOG_CLK_ENABLE();

  /*Configure GPIO pin Output Level */
  HAL_GPIO_WritePin(GPIOH, qtr_ctrl_odd_Pin|qtr_ctrl_even_Pin, GPIO_PIN_RESET);

  /*Configure GPIO pin Output Level */
  HAL_GPIO_WritePin(GPIOB, lid1_pwr_en_Pin|lid2_pwr_en_Pin|lid3_pwr_en_Pin|cmdLeds_Pin, GPIO_PIN_RESET);

  /*Configure GPIO pin Output Level */
  HAL_GPIO_WritePin(lid6_pwr_en_GPIO_Port, lid6_pwr_en_Pin, GPIO_PIN_RESET);

  /*Configure GPIO pin Output Level */
  HAL_GPIO_WritePin(GPIOD, Spare7_Pin|led3_Pin|led2_Pin, GPIO_PIN_RESET);

  /*Configure GPIO pin Output Level */
  HAL_GPIO_WritePin(GPIOG, Spare6_Pin|Spare5_Pin|Spare4_Pin|Spare3_Pin
                          |Spare2_Pin|Spare1_Pin|Spare0_Pin|led1_Pin, GPIO_PIN_RESET);

  /*Configure GPIO pin Output Level */
  HAL_GPIO_WritePin(lid4_pwr_en_GPIO_Port, lid4_pwr_en_Pin, GPIO_PIN_RESET);

  /*Configure GPIO pin Output Level */
  HAL_GPIO_WritePin(lid5_pwr_en_GPIO_Port, lid5_pwr_en_Pin, GPIO_PIN_RESET);

  /*Configure GPIO pins : qtr_ctrl_odd_Pin qtr_ctrl_even_Pin */
  GPIO_InitStruct.Pin = qtr_ctrl_odd_Pin|qtr_ctrl_even_Pin;
  GPIO_InitStruct.Mode = GPIO_MODE_OUTPUT_PP;
  GPIO_InitStruct.Pull = GPIO_NOPULL;
  GPIO_InitStruct.Speed = GPIO_SPEED_FREQ_LOW;
  HAL_GPIO_Init(GPIOH, &GPIO_InitStruct);

  /*Configure GPIO pins : lid1_pwr_en_Pin lid2_pwr_en_Pin lid3_pwr_en_Pin cmdLeds_Pin */
  GPIO_InitStruct.Pin = lid1_pwr_en_Pin|lid2_pwr_en_Pin|lid3_pwr_en_Pin|cmdLeds_Pin;
  GPIO_InitStruct.Mode = GPIO_MODE_OUTPUT_PP;
  GPIO_InitStruct.Pull = GPIO_NOPULL;
  GPIO_InitStruct.Speed = GPIO_SPEED_FREQ_LOW;
  HAL_GPIO_Init(GPIOB, &GPIO_InitStruct);

  /*Configure GPIO pin : lid6_pwr_en_Pin */
  GPIO_InitStruct.Pin = lid6_pwr_en_Pin;
  GPIO_InitStruct.Mode = GPIO_MODE_OUTPUT_PP;
  GPIO_InitStruct.Pull = GPIO_NOPULL;
  GPIO_InitStruct.Speed = GPIO_SPEED_FREQ_LOW;
  HAL_GPIO_Init(lid6_pwr_en_GPIO_Port, &GPIO_InitStruct);

  /*Configure GPIO pins : Spare7_Pin led3_Pin led2_Pin */
  GPIO_InitStruct.Pin = Spare7_Pin|led3_Pin|led2_Pin;
  GPIO_InitStruct.Mode = GPIO_MODE_OUTPUT_PP;
  GPIO_InitStruct.Pull = GPIO_NOPULL;
  GPIO_InitStruct.Speed = GPIO_SPEED_FREQ_LOW;
  HAL_GPIO_Init(GPIOD, &GPIO_InitStruct);

  /*Configure GPIO pins : Spare6_Pin Spare5_Pin Spare4_Pin Spare3_Pin
                           Spare2_Pin Spare1_Pin Spare0_Pin led1_Pin */
  GPIO_InitStruct.Pin = Spare6_Pin|Spare5_Pin|Spare4_Pin|Spare3_Pin
                          |Spare2_Pin|Spare1_Pin|Spare0_Pin|led1_Pin;
  GPIO_InitStruct.Mode = GPIO_MODE_OUTPUT_PP;
  GPIO_InitStruct.Pull = GPIO_NOPULL;
  GPIO_InitStruct.Speed = GPIO_SPEED_FREQ_LOW;
  HAL_GPIO_Init(GPIOG, &GPIO_InitStruct);

  /*Configure GPIO pin : lid4_pwr_en_Pin */
  GPIO_InitStruct.Pin = lid4_pwr_en_Pin;
  GPIO_InitStruct.Mode = GPIO_MODE_OUTPUT_PP;
  GPIO_InitStruct.Pull = GPIO_NOPULL;
  GPIO_InitStruct.Speed = GPIO_SPEED_FREQ_LOW;
  HAL_GPIO_Init(lid4_pwr_en_GPIO_Port, &GPIO_InitStruct);

  /*Configure GPIO pin : lid5_pwr_en_Pin */
  GPIO_InitStruct.Pin = lid5_pwr_en_Pin;
  GPIO_InitStruct.Mode = GPIO_MODE_OUTPUT_PP;
  GPIO_InitStruct.Pull = GPIO_NOPULL;
  GPIO_InitStruct.Speed = GPIO_SPEED_FREQ_LOW;
  HAL_GPIO_Init(lid5_pwr_en_GPIO_Port, &GPIO_InitStruct);

  /*Configure GPIO pins : boutonExt1_Pin boutonExt2_Pin */
  GPIO_InitStruct.Pin = boutonExt1_Pin|boutonExt2_Pin;
  GPIO_InitStruct.Mode = GPIO_MODE_INPUT;
  GPIO_InitStruct.Pull = GPIO_NOPULL;
  HAL_GPIO_Init(GPIOD, &GPIO_InitStruct);

  /*Configure GPIO pins : bouton3_Pin bouton2_Pin bouton1_Pin */
  GPIO_InitStruct.Pin = bouton3_Pin|bouton2_Pin|bouton1_Pin;
  GPIO_InitStruct.Mode = GPIO_MODE_INPUT;
  GPIO_InitStruct.Pull = GPIO_NOPULL;
  HAL_GPIO_Init(GPIOG, &GPIO_InitStruct);

}

void Error_Handler(void)
{
  __disable_irq();
  while (1)
  {
  }
}

/************************ (C) COPYRIGHT STMicroelectronics *****END OF FILE****/
